# f280015x_analog_subsys_regs register map
Vendor: Texas Instruments
Peripheral module from a debugger description file (folder C2000).
Address unit: 16 bits
Registers are 32-bit, read-write, no defined reset value unless marked. A register's access mark holds for its fields unless they carry their own. Offsets are as the file gives them; lines under a group give offsets from that group; [hi:lo] are bit positions; {n}, {i} and the like mark numbered series; 'fields as' and 'values as' point back to an identical list; <NAME> marks a mode.

## ANALOG_SUBSYS_REGS — ANALOG SUBSYS Registers
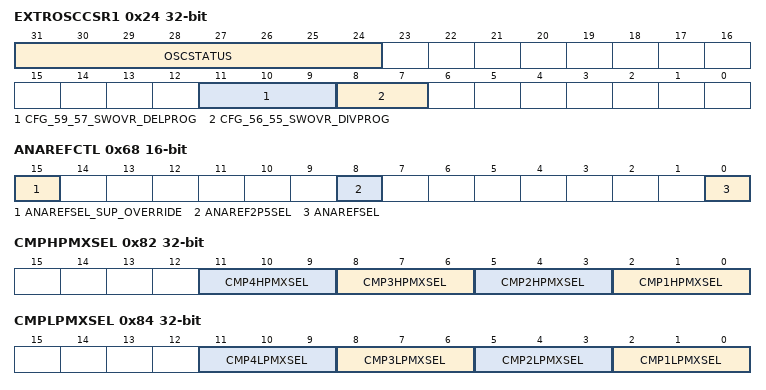
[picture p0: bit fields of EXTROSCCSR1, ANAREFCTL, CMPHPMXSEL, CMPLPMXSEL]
0x24 EXTROSCCSR1 access per field — External R based Oscillator Control and Status Register
  [31:24] OSCSTATUS ro — Observing EXTR signals
  [11:9] CFG_59_57_SWOVR_DELPROG rw — COUNTER DELAY config
  [8:7] CFG_56_55_SWOVR_DIVPROG rw — CFG_COUNTER_DIV
0x5E CONFIGLOCK — Lock Register for all the config registers.
  [3] AGPIOCTRL — Locks all AGPIOCTRL Register
0x60 TSNSCTL 16-bit — Temperature Sensor Control Register
  [0] ENABLE — Temperature Sensor Enable
0x68 ANAREFCTL 16-bit — Analog Reference Control Register. This register is not configurable for 32QFN package
  [15] ANAREFSEL_SUP_OVERRIDE — Control for overriding the analog reference with VDDA/VSSA
  [8] ANAREF2P5SEL — Analog Reference Select
  [0] ANAREFSEL — Analog Reference Select
0x70 VMONCTL 16-bit — Voltage Monitor Control Register
  [8] BORLVMONDIS — Disable BORL(ow) feature on VDDIO
0x82 CMPHPMXSEL — Bits to select one of the many sources on CompHP inputs. Refer to Pimux diagram for details.
  [3n-1:3n-3] CMP{n}HPMXSEL (n=1..4) — CMP{n}HPMXSEL bits
0x84 CMPLPMXSEL — Bits to select one of the many sources on CompLP inputs. Refer to Pimux diagram for details.
  [3n-1:3n-3] CMP{n}LPMXSEL (n=1..4) — CMP{n}LPMXSEL bits
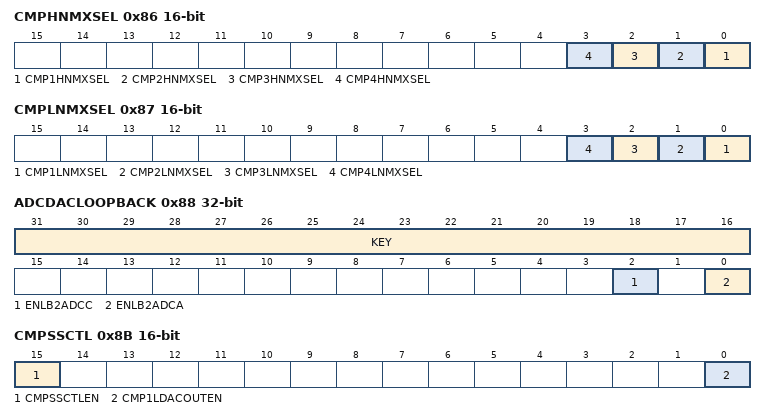
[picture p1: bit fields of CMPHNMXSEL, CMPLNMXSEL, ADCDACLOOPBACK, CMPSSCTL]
0x86 CMPHNMXSEL 16-bit — Bits to select one of the many sources on CompHN inputs. Refer to Pimux diagram for details.
  [n-1] CMP{n}HNMXSEL (n=1..4) — CMP{n}HNMXSEL bits
0x87 CMPLNMXSEL 16-bit — Bits to select one of the many sources on CompLN inputs. Refer to Pimux diagram for details.
  [n-1] CMP{n}LNMXSEL (n=1..4) — CMP{n}LNMXSEL bits
0x88 ADCDACLOOPBACK — Enabble loopback from DAC to ADCs
  [31:16] KEY — Key to enable writes
  [2] ENLB2ADCC — Enable DACA loopback to ADCC
  [0] ENLB2ADCA — Enable DACA loopback to ADCA
0x8B CMPSSCTL 16-bit — CMPSS Control Register
  [15] CMPSSCTLEN — Enable the CMPSSCTL Register
  [0] CMP1LDACOUTEN — Enable general purpose DAC functionality for CMPSS1.COMPDACL
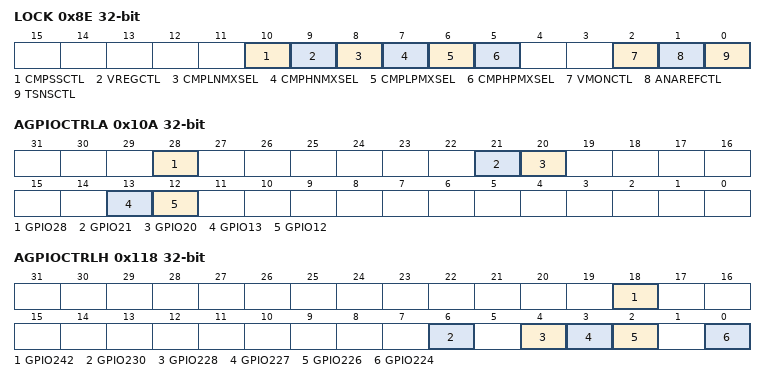
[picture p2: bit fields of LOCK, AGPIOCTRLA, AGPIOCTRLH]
0x8E LOCK
  [10] CMPSSCTL — CMPSSCTL Register lock bit
  [9] VREGCTL — VREGCTL Register lock bit
  [8] CMPLNMXSEL — CMPLNMXSEL Register lock bit
  [7] CMPHNMXSEL — CMPHNMXSEL Register lock bit
  [6] CMPLPMXSEL — CMPLPMXSEL Register lock bit
  [5] CMPHPMXSEL — CMPHPMXSEL Register lock bit
  [2] VMONCTL — VMONCTL Register lock bit
  [1] ANAREFCTL — ANAREFCTL Register lock bit
  [0] TSNSCTL — TSNSCTL Register lock bit
0x10A AGPIOCTRLA — AGPIO Control Register
  [28] GPIO28 — AGPIOCTRL for GPIO28
  [21] GPIO21 — AGPIOCTRL for GPIO21
  [20] GPIO20 — AGPIOCTRL for GPIO20
  [13] GPIO13 — AGPIOCTRL for GPIO13
  [12] GPIO12 — AGPIOCTRL for GPIO12
0x118 AGPIOCTRLH — AGPIO Control Register
  [18] GPIO242 — AGPIOCTRL for GPIO242
  [6] GPIO230 — AGPIOCTRL for GPIO230
  [4] GPIO228 — AGPIOCTRL for GPIO228
  [3] GPIO227 — AGPIOCTRL for GPIO227
  [2] GPIO226 — AGPIOCTRL for GPIO226
  [0] GPIO224 — AGPIOCTRL for GPIO224
